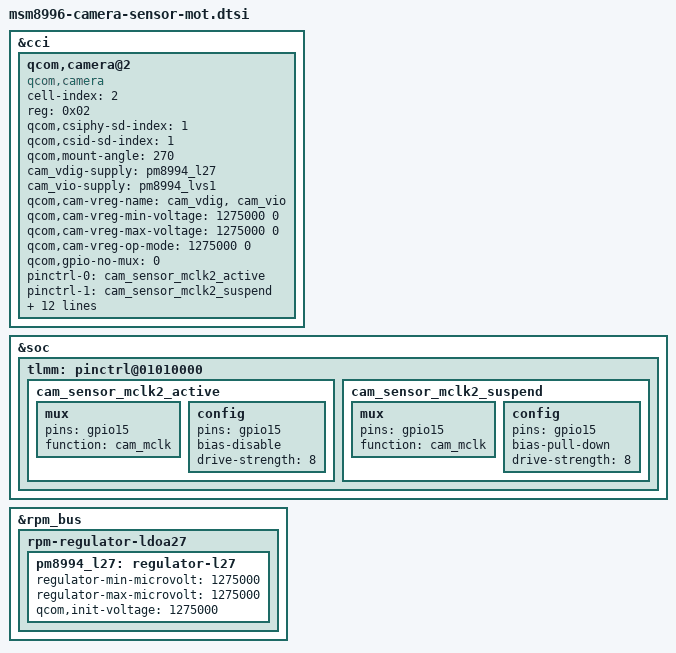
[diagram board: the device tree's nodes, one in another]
/*
 * Copyright (c) 2015 The Linux Foundation. All rights reserved.
 *
 * This program is free software; you can redistribute it and/or modify
 * it under the terms of the GNU General Public License version 2 and
 * only version 2 as published by the Free Software Foundation.
 *
 * This program is distributed in the hope that it will be useful,
 * but WITHOUT ANY WARRANTY; without even the implied warranty of
 * MERCHANTABILITY or FITNESS FOR A PARTICULAR PURPOSE.  See the
 * GNU General Public License for more details.
 */

&cci {
	/* ov5693 */
	qcom,camera@2 {
		cell-index = <2>;
		compatible = "qcom,camera";
		reg = <0x02>;
		qcom,csiphy-sd-index = <1>;
		qcom,csid-sd-index = <1>;
		qcom,mount-angle = <270>;
		cam_vdig-supply = <&pm8994_l27>;
		cam_vio-supply = <&pm8994_lvs1>;
		qcom,cam-vreg-name = "cam_vdig", "cam_vio";
		qcom,cam-vreg-min-voltage = <1275000 0>;
		qcom,cam-vreg-max-voltage = <1275000 0>;
		qcom,cam-vreg-op-mode = <1275000 0>;
		qcom,gpio-no-mux = <0>;
		pinctrl-names = "cam_default", "cam_suspend";
		pinctrl-0 = <&cam_sensor_mclk2_active>;
		pinctrl-1 = <&cam_sensor_mclk2_suspend>;
		gpios = <&tlmm 15 0>,
			<&tlmm 16 0>,
			<&tlmm 20 0>;
		qcom,gpio-reset = <1>;
		qcom,gpio-vana = <2>;
		qcom,gpio-req-tbl-num = <0 1 2>;
		qcom,gpio-req-tbl-flags = <1 0 0>;
		qcom,gpio-req-tbl-label = "CAMIF_MCLK2",
					  "CAM_RESET2",
					  "CAM_VANA";
		qcom,sensor-position = <1>;
		qcom,sensor-mode = <0>;
		qcom,cci-master = <0>;
		status = "ok";
		clocks = <&clock_mmss clk_mclk2_clk_src>,
			<&clock_mmss clk_camss_mclk2_clk>;
		clock-names = "cam_src_clk", "cam_clk";
	};
};

&soc {
	tlmm: pinctrl@01010000 {
		cam_sensor_mclk2_active: cam_sensor_mclk2_active {
			/* MCLK2 */
			mux {
				/* CLK, DATA */
				pins = "gpio15";
				function = "cam_mclk";
			};

			config {
				pins = "gpio15";
				bias-disable; /* No PULL */
				drive-strength = <8>; /* 8 MA */
			};
		};

		cam_sensor_mclk2_suspend: cam_sensor_mclk2_suspend{
			/* MCLK2 */
			mux {
				/* CLK, DATA */
				pins = "gpio15";
				function = "cam_mclk";
			};

			config {
				pins = "gpio15";
				bias-pull-down; /* PULL DOWN */
				drive-strength = <8>; /* 8 MA */
			};
		};
	};
};

&rpm_bus {
	rpm-regulator-ldoa27 {
		status = "okay";
		pm8994_l27: regulator-l27 {
			regulator-min-microvolt = <1275000>;
			regulator-max-microvolt = <1275000>;
			qcom,init-voltage = <1275000>;
			status = "okay";
		};
	};
};
